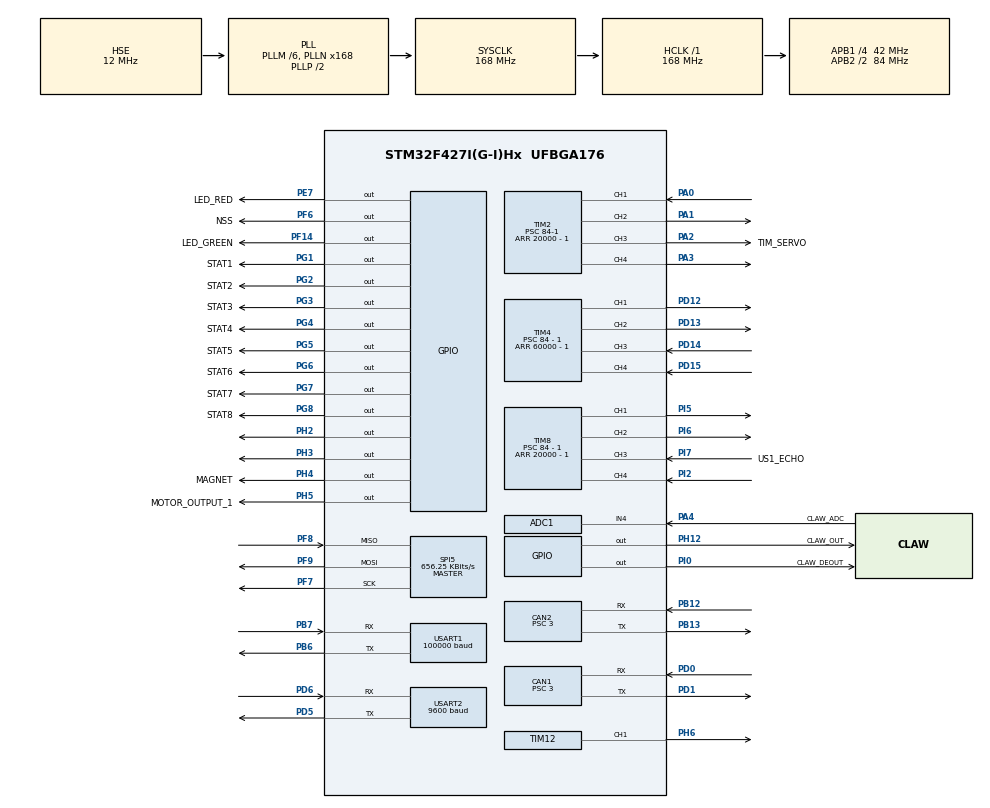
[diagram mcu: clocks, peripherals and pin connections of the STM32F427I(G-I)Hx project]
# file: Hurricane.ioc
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ADC1.Channel-16\#ChannelRegularConversion=ADC_CHANNEL_4
ADC1.ClockPrescaler=ADC_CLOCK_SYNC_PCLK_DIV4
ADC1.ContinuousConvMode=ENABLE
ADC1.DMAContinuousRequests=DISABLE
ADC1.DataAlign=ADC_DATAALIGN_RIGHT
ADC1.DiscontinuousConvMode=DISABLE
ADC1.EOCSelection=ADC_EOC_SEQ_CONV
ADC1.EnableAnalogWatchDog=false
ADC1.ExternalTrigConv=ADC_SOFTWARE_START
ADC1.ExternalTrigConvEdge=ADC_EXTERNALTRIGCONVEDGE_NONE
ADC1.InjNumberOfConversion=0
ADC1.NbrOfConversion=1
ADC1.NbrOfConversionFlag=1
ADC1.Rank-16\#ChannelRegularConversion=1
ADC1.Resolution=ADC_RESOLUTION_12B
ADC1.SamplingTime-16\#ChannelRegularConversion=ADC_SAMPLETIME_480CYCLES
ADC1.ScanConvMode=DISABLE
ADC1.master=1
CAN1.BS1=CAN_BS1_9TQ
CAN1.BS2=CAN_BS2_4TQ
CAN1.CalculateTimeBit=1000
CAN1.CalculateTimeQuantum=71.42857142857143
CAN1.Prescaler=3
CAN2.BS1=CAN_BS1_9TQ
CAN2.BS2=CAN_BS2_4TQ
CAN2.CalculateTimeBit=1000
CAN2.CalculateTimeQuantum=71.42857142857143
CAN2.Prescaler=3
Dma.Request0=USART1_RX
Dma.Request1=USART2_RX
Dma.USART1_RX.0.Direction=DMA_PERIPH_TO_MEMORY
Dma.USART1_RX.0.FIFOMode=DMA_FIFOMODE_DISABLE
Dma.USART1_RX.0.Instance=DMA2_Stream2
Dma.USART1_RX.0.MemDataAlignment=DMA_MDATAALIGN_BYTE
Dma.USART1_RX.0.MemInc=DMA_MINC_ENABLE
Dma.USART1_RX.0.Mode=DMA_CIRCULAR
Dma.USART1_RX.0.PeriphDataAlignment=DMA_PDATAALIGN_BYTE
Dma.USART1_RX.0.PeriphInc=DMA_PINC_DISABLE
Dma.USART1_RX.0.Priority=DMA_PRIORITY_LOW
Dma.USART2_RX.1.Direction=DMA_PERIPH_TO_MEMORY
Dma.USART2_RX.1.FIFOMode=DMA_FIFOMODE_DISABLE
Dma.USART2_RX.1.Instance=DMA1_Stream5
Dma.USART2_RX.1.MemDataAlignment=DMA_MDATAALIGN_BYTE
Dma.USART2_RX.1.MemInc=DMA_MINC_ENABLE
Dma.USART2_RX.1.Mode=DMA_NORMAL
Dma.USART2_RX.1.PeriphDataAlignment=DMA_PDATAALIGN_BYTE
Dma.USART2_RX.1.PeriphInc=DMA_PINC_DISABLE
Dma.USART2_RX.1.Priority=DMA_PRIORITY_LOW
IWDG.Prescaler=IWDG_PRESCALER_256
Mcu.Family=STM32F4
Mcu.Name=STM32F427I(G-I)Hx
Mcu.Package=UFBGA176
NVIC.ADC_IRQn=true\:0\:0\:false\:false\:true\:true
NVIC.CAN1_RX0_IRQn=true\:0\:0\:true\:false\:true\:true
NVIC.CAN1_TX_IRQn=true\:0\:0\:true\:false\:true\:true
NVIC.CAN2_RX0_IRQn=true\:1\:0\:true\:false\:true\:true
NVIC.CAN2_TX_IRQn=true\:2\:0\:true\:false\:true\:true
NVIC.DMA1_Stream5_IRQn=true\:0\:0\:false\:false\:true\:false
NVIC.DMA2_Stream2_IRQn=true\:0\:0\:false\:false\:true\:false
NVIC.PriorityGroup=NVIC_PRIORITYGROUP_4
NVIC.TIM1_UP_TIM10_IRQn=true\:4\:0\:true\:false\:true\:true
NVIC.TIM2_IRQn=true\:0\:0\:false\:false\:true\:true
NVIC.TIM4_IRQn=true\:0\:0\:false\:false\:true\:true
NVIC.TIM6_DAC_IRQn=true\:3\:0\:true\:false\:true\:true
NVIC.TIM7_IRQn=true\:0\:0\:true\:false\:true\:true
NVIC.TIM8_CC_IRQn=true\:0\:0\:false\:false\:true\:true
NVIC.USART1_IRQn=true\:0\:0\:true\:false\:true\:true
NVIC.USART2_IRQn=true\:1\:0\:true\:false\:true\:true
PA0/WKUP.Signal=S_TIM2_CH1_ETR
PA1.Signal=S_TIM2_CH2
PA2.GPIO_Label=TIM_SERVO
PA2.Signal=S_TIM2_CH3
PA3.Signal=S_TIM2_CH4
PA4.GPIO_Label=CLAW_ADC
PA4.Signal=ADCx_IN4
PB12.Mode=Slave
PB12.Signal=CAN2_RX
PB13.Mode=Slave
PB13.Signal=CAN2_TX
PB6.Mode=Asynchronous
PB6.Signal=USART1_TX
PB7.Mode=Asynchronous
PB7.Signal=USART1_RX
PD0.Mode=Master
PD0.Signal=CAN1_RX
PD1.Mode=Master
PD1.Signal=CAN1_TX
PD12.Signal=S_TIM4_CH1
PD13.Signal=S_TIM4_CH2
PD14.Signal=S_TIM4_CH3
PD15.Signal=S_TIM4_CH4
PD5.Mode=Asynchronous
PD5.Signal=USART2_TX
PD6.Mode=Asynchronous
PD6.Signal=USART2_RX
PE7.GPIO_Label=LED_RED
PE7.Signal=GPIO_Output
PF14.GPIO_Label=LED_GREEN
PF14.Signal=GPIO_Output
PF6.GPIO_Label=NSS
PF6.Signal=GPIO_Output
PF7.Mode=Full_Duplex_Master
PF7.Signal=SPI5_SCK
PF8.Mode=Full_Duplex_Master
PF8.Signal=SPI5_MISO
PF9.Mode=Full_Duplex_Master
PF9.Signal=SPI5_MOSI
PG1.GPIO_Label=STAT1
PG1.Signal=GPIO_Output
PG2.GPIO_Label=STAT2
PG2.Signal=GPIO_Output
PG3.GPIO_Label=STAT3
PG3.Signal=GPIO_Output
PG4.GPIO_Label=STAT4
PG4.Signal=GPIO_Output
PG5.GPIO_Label=STAT5
PG5.Signal=GPIO_Output
PG6.GPIO_Label=STAT6
PG6.Signal=GPIO_Output
PG7.GPIO_Label=STAT7
PG7.Signal=GPIO_Output
PG8.GPIO_Label=STAT8
PG8.Signal=GPIO_Output
PH0/OSC_IN.Mode=HSE-External-Oscillator
PH0/OSC_IN.Signal=RCC_OSC_IN
PH1/OSC_OUT.Mode=HSE-External-Oscillator
PH1/OSC_OUT.Signal=RCC_OSC_OUT
PH12.GPIO_Label=CLAW_OUT
PH12.Signal=GPIO_Output
PH2.PinState=GPIO_PIN_SET
PH2.Signal=GPIO_Output
PH3.PinState=GPIO_PIN_SET
PH3.Signal=GPIO_Output
PH4.GPIO_Label=MAGNET
PH4.Signal=GPIO_Output
PH5.GPIO_Label=MOTOR_OUTPUT_1
PH5.PinState=GPIO_PIN_SET
PH5.Signal=GPIO_Output
PH6.Signal=S_TIM12_CH1
PI0.GPIO_Label=CLAW_DEOUT
PI0.Signal=GPIO_Output
PI2.Signal=S_TIM8_CH4
PI5.Signal=S_TIM8_CH1
PI6.Signal=S_TIM8_CH2
PI7.GPIO_Label=US1_ECHO
PI7.Signal=S_TIM8_CH3
ProjectManager.HeapSize=0x200
ProjectManager.StackSize=0x400
ProjectManager.TargetToolchain=SW4STM32
RCC.48MHZClocksFreq_Value=84000000
RCC.AHBFreq_Value=168000000
RCC.APB1CLKDivider=RCC_HCLK_DIV4
RCC.APB1Freq_Value=42000000
RCC.APB1TimFreq_Value=84000000
RCC.APB2CLKDivider=RCC_HCLK_DIV2
RCC.APB2Freq_Value=84000000
RCC.APB2TimFreq_Value=168000000
RCC.CortexFreq_Value=168000000
RCC.HCLKFreq_Value=168000000
RCC.HSE_VALUE=12000000
RCC.HSI_VALUE=16000000
RCC.LSE_VALUE=32768
RCC.PLLM=6
RCC.PLLN=168
RCC.PLLSourceVirtual=RCC_PLLSOURCE_HSE
RCC.SYSCLKFreq_VALUE=168000000
RCC.SYSCLKSource=RCC_SYSCLKSOURCE_PLLCLK
RCC.VCOOutputFreq_Value=336000000
SH.ADCx_IN4.0=ADC1_IN4,IN4
SH.S_TIM12_CH1.0=TIM12_CH1,PWM Generation1 CH1
SH.S_TIM2_CH1_ETR.0=TIM2_CH1,Input_Capture1_from_TI1
SH.S_TIM2_CH2.0=TIM2_CH2,PWM Generation2 CH2
SH.S_TIM2_CH3.0=TIM2_CH3,PWM Generation3 CH3
SH.S_TIM2_CH4.0=TIM2_CH4,PWM Generation4 CH4
SH.S_TIM4_CH1.0=TIM4_CH1,PWM Generation1 CH1
SH.S_TIM4_CH2.0=TIM4_CH2,PWM Generation2 CH2
SH.S_TIM4_CH3.0=TIM4_CH3,Input_Capture3_from_TI3
SH.S_TIM4_CH4.0=TIM4_CH4,Input_Capture4_from_TI4
SH.S_TIM8_CH1.0=TIM8_CH1,PWM Generation1 CH1
SH.S_TIM8_CH2.0=TIM8_CH2,PWM Generation2 CH2
SH.S_TIM8_CH3.0=TIM8_CH3,Input_Capture3_from_TI3
SH.S_TIM8_CH4.0=TIM8_CH4,Input_Capture4_from_TI4
SPI5.BaudRatePrescaler=SPI_BAUDRATEPRESCALER_128
SPI5.CalculateBaudRate=656.25 KBits/s
SPI5.Direction=SPI_DIRECTION_2LINES
SPI5.Mode=SPI_MODE_MASTER
SPI5.VirtualType=VM_MASTER
TIM10.Period=10000
TIM10.Prescaler=168-1
TIM12.Channel-PWM\ Generation1\ CH1=TIM_CHANNEL_1
TIM12.Period=2500-1
TIM12.Prescaler=84-1
TIM12.Pulse-PWM\ Generation1\ CH1=1000
TIM2.Channel-Input_Capture1_from_TI1=TIM_CHANNEL_1
TIM2.Channel-PWM\ Generation2\ CH2=TIM_CHANNEL_2
TIM2.Channel-PWM\ Generation3\ CH3=TIM_CHANNEL_3
TIM2.Channel-PWM\ Generation4\ CH4=TIM_CHANNEL_4
TIM2.ICPolarity_CH1=TIM_INPUTCHANNELPOLARITY_BOTHEDGE
TIM2.OCMode_PWM-PWM\ Generation3\ CH3=TIM_OCMODE_PWM1
TIM2.Period=20000 - 1
TIM2.Prescaler=84-1
TIM2.Pulse-PWM\ Generation4\ CH4=0
TIM4.Channel-Input_Capture3_from_TI3=TIM_CHANNEL_3
TIM4.Channel-Input_Capture4_from_TI4=TIM_CHANNEL_4
TIM4.Channel-PWM\ Generation1\ CH1=TIM_CHANNEL_1
TIM4.Channel-PWM\ Generation2\ CH2=TIM_CHANNEL_2
TIM4.ICFilter_CH3=0xf
TIM4.ICFilter_CH4=0xf
TIM4.ICPolarity_CH3=TIM_INPUTCHANNELPOLARITY_BOTHEDGE
TIM4.ICPolarity_CH4=TIM_INPUTCHANNELPOLARITY_BOTHEDGE
TIM4.Period=60000 - 1
TIM4.Prescaler=84 - 1
TIM4.Pulse-PWM\ Generation1\ CH1=20
TIM4.Pulse-PWM\ Generation2\ CH2=20
TIM5.Period=20000 - 1
TIM5.Prescaler=84 - 1
TIM6.Period=2000
TIM6.Prescaler=84-1
TIM7.Period=1000
TIM7.Prescaler=84-1
TIM8.Channel-Input_Capture3_from_TI3=TIM_CHANNEL_3
TIM8.Channel-Input_Capture4_from_TI4=TIM_CHANNEL_4
TIM8.Channel-PWM\ Generation1\ CH1=TIM_CHANNEL_1
TIM8.Channel-PWM\ Generation2\ CH2=TIM_CHANNEL_2
TIM8.ICFilter_CH3=0xf
TIM8.ICFilter_CH4=0xf
TIM8.ICPolarity_CH3=TIM_INPUTCHANNELPOLARITY_BOTHEDGE
TIM8.ICPolarity_CH4=TIM_INPUTCHANNELPOLARITY_BOTHEDGE
TIM8.Period=20000 - 1
TIM8.Prescaler=84 - 1
TIM8.Pulse-PWM\ Generation2\ CH2=20
USART1.BaudRate=100000
USART1.Mode=MODE_RX
USART1.Parity=PARITY_EVEN
USART1.VirtualMode=VM_ASYNC
USART1.WordLength=WORDLENGTH_8B
USART2.BaudRate=9600
USART2.VirtualMode=VM_ASYNC
VP_IWDG_VS_IWDG.Mode=IWDG_Activate
VP_TIM10_VS_ClockSourceINT.Mode=Enable_Timer
VP_TIM12_VS_ClockSourceINT.Mode=Internal
VP_TIM2_VS_ClockSourceINT.Mode=Internal
VP_TIM4_VS_ClockSourceINT.Mode=Internal
VP_TIM5_VS_ClockSourceINT.Mode=Internal
VP_TIM6_VS_ClockSourceINT.Mode=Enable_Timer
VP_TIM7_VS_ClockSourceINT.Mode=Enable_Timer
VP_TIM8_VS_ClockSourceINT.Mode=Internal
board=Hurricane

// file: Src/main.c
/**
  ******************************************************************************
  * @file           : main.c
  * @brief          : Main program body
  ******************************************************************************
  ** This notice applies to any and all portions of this file
  * that are not between comment pairs USER CODE BEGIN and
  * USER CODE END. Other portions of this file, whether
  * inserted by the user or by software development tools
  * are owned by their respective copyright owners.
  *
  * COPYRIGHT(c) 2018 STMicroelectronics
  *
  * Redistribution and use in source and binary forms, with or without modification,
  * are permitted provided that the following conditions are met:
  *   1. Redistributions of source code must retain the above copyright notice,
  *      this list of conditions and the following disclaimer.
  *   2. Redistributions in binary form must reproduce the above copyright notice,
  *      this list of conditions and the following disclaimer in the documentation
  *      and/or other materials provided with the distribution.
  *   3. Neither the name of STMicroelectronics nor the names of its contributors
  *      may be used to endorse or promote products derived from this software
  *      without specific prior written permission.
  *
  * THIS SOFTWARE IS PROVIDED BY THE COPYRIGHT HOLDERS AND CONTRIBUTORS "AS IS"
  * AND ANY EXPRESS OR IMPLIED WARRANTIES, INCLUDING, BUT NOT LIMITED TO, THE
  * IMPLIED WARRANTIES OF MERCHANTABILITY AND FITNESS FOR A PARTICULAR PURPOSE ARE
  * DISCLAIMED. IN NO EVENT SHALL THE COPYRIGHT HOLDER OR CONTRIBUTORS BE LIABLE
  * FOR ANY DIRECT, INDIRECT, INCIDENTAL, SPECIAL, EXEMPLARY, OR CONSEQUENTIAL
  * DAMAGES (INCLUDING, BUT NOT LIMITED TO, PROCUREMENT OF SUBSTITUTE GOODS OR
  * SERVICES; LOSS OF USE, DATA, OR PROFITS; OR BUSINESS INTERRUPTION) HOWEVER
  * CAUSED AND ON ANY THEORY OF LIABILITY, WHETHER IN CONTRACT, STRICT LIABILITY,
  * OR TORT (INCLUDING NEGLIGENCE OR OTHERWISE) ARISING IN ANY WAY OUT OF THE USE
  * OF THIS SOFTWARE, EVEN IF ADVISED OF THE POSSIBILITY OF SUCH DAMAGE.
  *
  ******************************************************************************
  */
#include "main.h"
#include "stm32f4xx_hal.h"
#include "adc.h"
#include "can.h"
#include "dma.h"
#include "iwdg.h"
#include "spi.h"
#include "tim.h"
#include "usart.h"
#include "gpio.h"

/* USER CODE BEGIN Includes */
#include <string.h>
#include <stdlib.h>
#include "../Src-CAH/bootstrap.h"
/* USER CODE END Includes */

/* USER CODE BEGIN PV */
/* Private variables ---------------------------------------------------------*/

/* USER CODE END PV */

void SystemClock_Config(void);

/* USER CODE BEGIN PFP */
/* Private function prototypes -----------------------------------------------*/

/* USER CODE END PFP */

/* USER CODE BEGIN 0 */
extern void initialise_monitor_handles(void);
/* USER CODE END 0 */

int main(void)
{

  /* MCU Configuration----------------------------------------------------------*/

  /* Reset of all peripherals, Initializes the Flash interface and the Systick. */
  HAL_Init();

  /* Configure the system clock */
  SystemClock_Config();

  /* Initialize all configured peripherals */
  MX_GPIO_Init();
  MX_DMA_Init();
  MX_CAN1_Init();
  MX_CAN2_Init();
  MX_SPI5_Init();
  MX_USART1_UART_Init();
  MX_TIM6_Init();
  MX_TIM12_Init();
  MX_USART2_UART_Init();
  MX_TIM7_Init();
  MX_TIM10_Init();
  MX_TIM2_Init();
  MX_IWDG_Init();
  MX_TIM8_Init();
  MX_TIM5_Init();
  MX_ADC1_Init();
  MX_TIM4_Init();
  /* USER CODE BEGIN 2 */
    charr_bootstrap();
  /* USER CODE END 2 */

  /* Infinite loop */
  /* USER CODE BEGIN WHILE */

    while (1) {
        charr_loop();
  /* USER CODE END WHILE */

    }

}

void SystemClock_Config(void)
{

  RCC_OscInitTypeDef RCC_OscInitStruct;
  RCC_ClkInitTypeDef RCC_ClkInitStruct;

    /**Configure the main internal regulator output voltage
    */
  __HAL_RCC_PWR_CLK_ENABLE();

  __HAL_PWR_VOLTAGESCALING_CONFIG(PWR_REGULATOR_VOLTAGE_SCALE1);

    /**Initializes the CPU, AHB and APB busses clocks
    */
  RCC_OscInitStruct.OscillatorType = RCC_OSCILLATORTYPE_LSI|RCC_OSCILLATORTYPE_HSE;
  RCC_OscInitStruct.HSEState = RCC_HSE_ON;
  RCC_OscInitStruct.LSIState = RCC_LSI_ON;
  RCC_OscInitStruct.PLL.PLLState = RCC_PLL_ON;
  RCC_OscInitStruct.PLL.PLLSource = RCC_PLLSOURCE_HSE;
  RCC_OscInitStruct.PLL.PLLM = 6;
  RCC_OscInitStruct.PLL.PLLN = 168;
  RCC_OscInitStruct.PLL.PLLP = RCC_PLLP_DIV2;
  RCC_OscInitStruct.PLL.PLLQ = 4;
  if (HAL_RCC_OscConfig(&RCC_OscInitStruct) != HAL_OK)
  {
    _Error_Handler(__FILE__, __LINE__);
  }

    /**Initializes the CPU, AHB and APB busses clocks
    */
  RCC_ClkInitStruct.ClockType = RCC_CLOCKTYPE_HCLK|RCC_CLOCKTYPE_SYSCLK
                              |RCC_CLOCKTYPE_PCLK1|RCC_CLOCKTYPE_PCLK2;
  RCC_ClkInitStruct.SYSCLKSource = RCC_SYSCLKSOURCE_PLLCLK;
  RCC_ClkInitStruct.AHBCLKDivider = RCC_SYSCLK_DIV1;
  RCC_ClkInitStruct.APB1CLKDivider = RCC_HCLK_DIV4;
  RCC_ClkInitStruct.APB2CLKDivider = RCC_HCLK_DIV2;

  if (HAL_RCC_ClockConfig(&RCC_ClkInitStruct, FLASH_LATENCY_5) != HAL_OK)
  {
    _Error_Handler(__FILE__, __LINE__);
  }

    /**Configure the Systick interrupt time
    */
  HAL_SYSTICK_Config(HAL_RCC_GetHCLKFreq()/1000);

    /**Configure the Systick
    */
  HAL_SYSTICK_CLKSourceConfig(SYSTICK_CLKSOURCE_HCLK);

  /* SysTick_IRQn interrupt configuration */
  HAL_NVIC_SetPriority(SysTick_IRQn, 0, 0);
}

void _Error_Handler(char *file, int line)
{
  /* USER CODE BEGIN Error_Handler_Debug */
    /* User can add his own implementation to report the HAL error return state */
    hurricane_error_handler(file, line);
    while (1) {
    }
  /* USER CODE END Error_Handler_Debug */
}

/************************ (C) COPYRIGHT STMicroelectronics *****END OF FILE****/
